# STM32L496 register map
File version: 1.0
CPU: CM4 r0p1, little endian, MPU, FPU, 4 interrupt priority bits
Registers are 32-bit, read-write, reset 0x0 unless marked. A register's access mark holds for its fields unless they carry their own. Offsets are from the block's base; [hi:lo] are bit positions; {n}, {i} and the like mark numbered series; 'fields as' and 'values as' point back to an identical list.

## HASH — Hash processor
Base 0x50060400
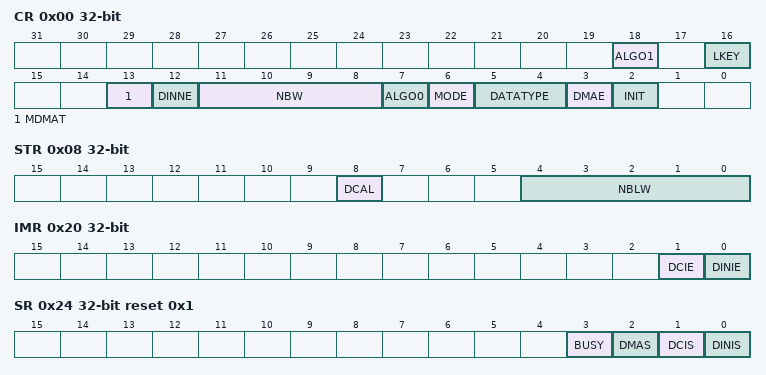
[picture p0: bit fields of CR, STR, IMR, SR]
0x00 CR access per field — control register
  [18] ALGO1 rw — ALGO
  [16] LKEY rw — Long key selection
  [13] MDMAT rw — Multiple DMA Transfers
  [12] DINNE ro — DIN not empty
  [11:8] NBW ro — Number of words already pushed
  [7] ALGO0 rw — Algorithm selection
  [6] MODE rw — Mode selection
  [5:4] DATATYPE rw — Data type selection
  [3] DMAE rw — DMA enable
  [2] INIT wo — Initialize message digest calculation
0x04 DIN — data input register
  [31:0] DATAIN — Data input
0x08 STR access per field — start register
  [8] DCAL wo — Digest calculation
  [4:0] NBLW rw — Number of valid bits in the last word of the message
0x0C HR0 ro — digest registers
  [31:0] H0
0x20 IMR — interrupt enable register
  [1] DCIE — Digest calculation completion interrupt enable
  [0] DINIE — Data input interrupt enable
0x24 SR access per field reset 0x1 — status register
  [3] BUSY ro — Busy bit
  [2] DMAS ro — DMA Status
  [1] DCIS rw — Digest calculation completion interrupt status
  [0] DINIS rw — Data input interrupt status
{0xF8+4i} CSR{i} (i=0..53) — context swap registers
0x310 HASH_HR0 ro — HASH digest register
  [31:0] H0
{0x310+4i} HASH_HR{i} ro (i=1..7) — read-only
  [31:0] H{i}

## DMA2D — DMA2D controller
Base 0x4002B000
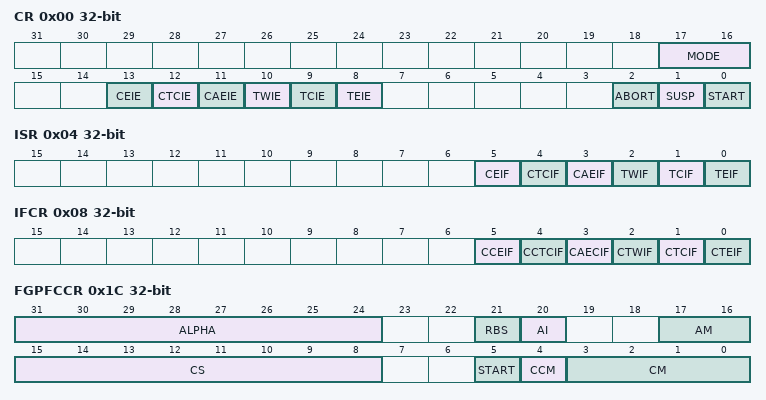
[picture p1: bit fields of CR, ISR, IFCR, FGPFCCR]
0x00 CR — control register
  [17:16] MODE — DMA2D mode
  [13] CEIE — Configuration Error Interrupt Enable
  [12] CTCIE — CLUT transfer complete interrupt enable
  [11] CAEIE — CLUT access error interrupt enable
  [10] TWIE — Transfer watermark interrupt enable
  [9] TCIE — Transfer complete interrupt enable
  [8] TEIE — Transfer error interrupt enable
  [2] ABORT
  [1] SUSP — Suspend
  [0] START
0x04 ISR ro — Interrupt Status Register
  [5] CEIF — Configuration error interrupt flag
  [4] CTCIF — CLUT transfer complete interrupt flag
  [3] CAEIF — CLUT access error interrupt flag
  [2] TWIF — Transfer watermark interrupt flag
  [1] TCIF — Transfer complete interrupt flag
  [0] TEIF — Transfer error interrupt flag
0x08 IFCR — interrupt flag clear register
  [5] CCEIF — Clear configuration error interrupt flag
  [4] CCTCIF — Clear CLUT transfer complete interrupt flag
  [3] CAECIF — Clear CLUT access error interrupt flag
  [2] CTWIF — Clear transfer watermark interrupt flag
  [1] CTCIF — Clear transfer complete interrupt flag
  [0] CTEIF — Clear Transfer error interrupt flag
0x0C FGMAR — foreground memory address register
  [31:0] MA — Memory address
0x10 FGOR — foreground offset register
  [13:0] LO — Line offset
0x14 BGMAR — background memory address register
  [31:0] MA — Memory address
0x18 BGOR — background offset register
  [13:0] LO — Line offset
0x1C FGPFCCR — foreground PFC control register
  [31:24] ALPHA — Alpha value
  [21] RBS — Red Blue Swap
  [20] AI — Alpha Inverted
  [17:16] AM — Alpha mode
  [15:8] CS — CLUT size
  [5] START
  [4] CCM — CLUT color mode
  [3:0] CM — Color mode
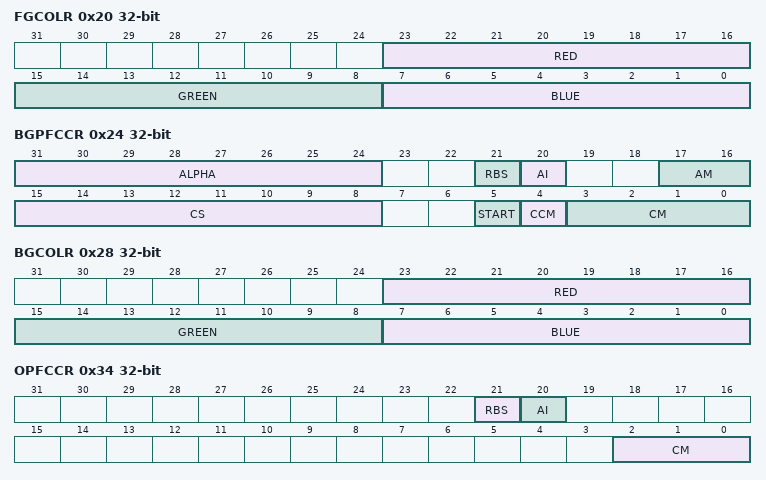
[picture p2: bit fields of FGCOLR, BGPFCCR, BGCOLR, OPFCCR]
0x20 FGCOLR — foreground color register
  [23:16] RED — Red Value
  [15:8] GREEN — Green Value
  [7:0] BLUE — Blue Value
0x24 BGPFCCR — background PFC control register
  [31:24] ALPHA — Alpha value
  [21] RBS — Red Blue Swap
  [20] AI — Alpha Inverted
  [17:16] AM — Alpha mode
  [15:8] CS — CLUT size
  [5] START
  [4] CCM — CLUT Color mode
  [3:0] CM — Color mode
0x28 BGCOLR — background color register
  fields as FGCOLR
0x2C FGCMAR — foreground CLUT memory address register
  [31:0] MA — Memory Address
0x30 BGCMAR — background CLUT memory address register
  [31:0] MA — Memory address
0x34 OPFCCR — output PFC control register
  [21] RBS — Red Blue Swap
  [20] AI — Alpha Inverted
  [2:0] CM — Color mode
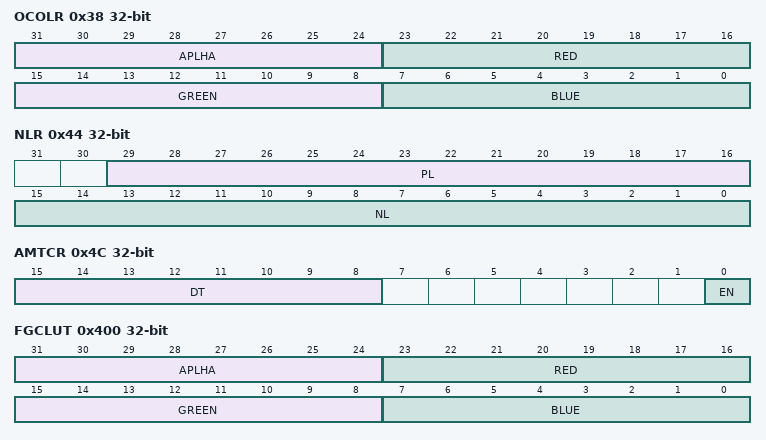
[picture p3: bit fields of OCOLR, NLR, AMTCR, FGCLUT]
0x38 OCOLR — output color register
  [31:24] APLHA — Alpha Channel Value
  [23:16] RED — Red Value
  [15:8] GREEN — Green Value
  [7:0] BLUE — Blue Value
0x3C OMAR — output memory address register
  [31:0] MA — Memory Address
0x40 OOR — output offset register
  [13:0] LO — Line Offset
0x44 NLR — number of line register
  [29:16] PL — Pixel per lines
  [15:0] NL — Number of lines
0x48 LWR — line watermark register
  [15:0] LW — Line watermark
0x4C AMTCR — AHB master timer configuration register
  [15:8] DT — Dead Time
  [0] EN — Enable
0x400 FGCLUT
  [31:24] APLHA, [23:16] RED, [15:8] GREEN, [7:0] BLUE
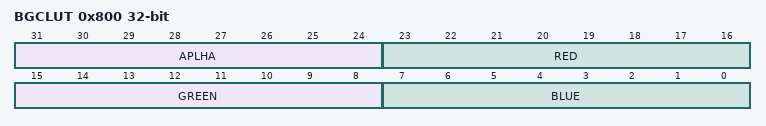
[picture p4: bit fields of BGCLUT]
0x800 BGCLUT
  [31:24] APLHA, [23:16] RED, [15:8] GREEN, [7:0] BLUE

## FPU — Floting point unit
Base 0xE000EF34
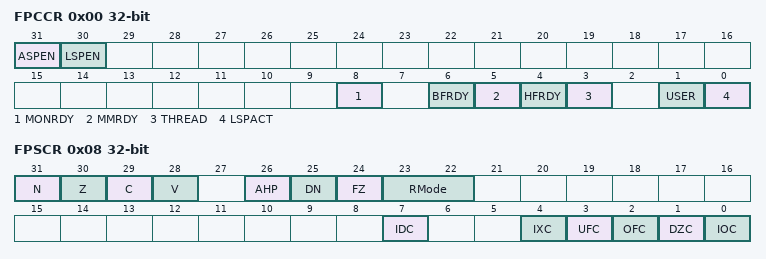
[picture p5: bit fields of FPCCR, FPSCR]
0x00 FPCCR — Floating-point context control register
  [31] ASPEN, [30] LSPEN, [8] MONRDY, [6] BFRDY, [5] MMRDY, [4] HFRDY, [3] THREAD, [1] USER, [0] LSPACT
0x04 FPCAR — Floating-point context address register
  [31:3] ADDRESS — Location of unpopulated floating-point
0x08 FPSCR — Floating-point status control register
  [31] N — Negative condition code flag
  [30] Z — Zero condition code flag
  [29] C — Carry condition code flag
  [28] V — Overflow condition code flag
  [26] AHP — Alternative half-precision control bit
  [25] DN — Default NaN mode control bit
  [24] FZ — Flush-to-zero mode control bit:
  [23:22] RMode — Rounding Mode control field
  [7] IDC — Input denormal cumulative exception bit.
  [4] IXC — Inexact cumulative exception bit
  [3] UFC — Underflow cumulative exception bit
  [2] OFC — Overflow cumulative exception bit
  [1] DZC — Division by zero cumulative exception bit.
  [0] IOC — Invalid operation cumulative exception bit

## MPU — Memory protection unit
Base 0xE000ED90
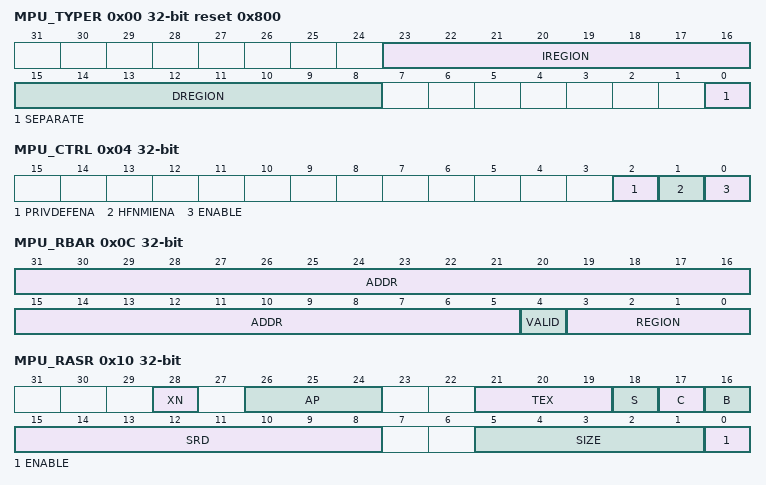
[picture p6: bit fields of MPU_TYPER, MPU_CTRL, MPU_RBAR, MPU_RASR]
0x00 MPU_TYPER ro reset 0x800 — MPU type register
  [23:16] IREGION — Number of MPU instruction regions
  [15:8] DREGION — Number of MPU data regions
  [0] SEPARATE — Separate flag
0x04 MPU_CTRL ro — MPU control register
  [2] PRIVDEFENA — Enable priviliged software access to default memory map
  [1] HFNMIENA — Enables the operation of MPU during hard fault
  [0] ENABLE — Enables the MPU
0x08 MPU_RNR — MPU region number register
  [7:0] REGION — MPU region
0x0C MPU_RBAR — MPU region base address register
  [31:5] ADDR — Region base address field
  [4] VALID — MPU region number valid
  [3:0] REGION — MPU region field
0x10 MPU_RASR — MPU region attribute and size register
  [28] XN — Instruction access disable bit
  [26:24] AP — Access permission
  [21:19] TEX — memory attribute
  [18] S — Shareable memory attribute
  [17] C — memory attribute
  [16] B — memory attribute
  [15:8] SRD — Subregion disable bits
  [5:1] SIZE — Size of the MPU protection region
  [0] ENABLE — Region enable bit.

## STK — SysTick timer
Base 0xE000E010
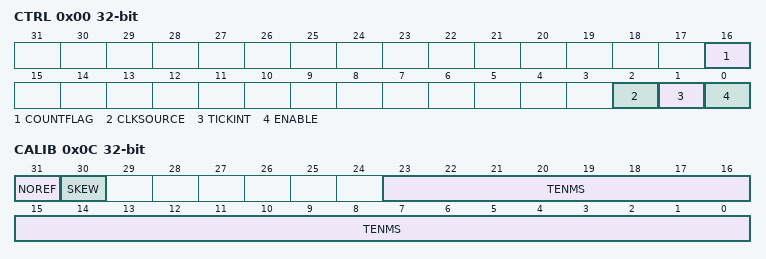
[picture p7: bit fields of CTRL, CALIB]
0x00 CTRL — SysTick control and status register
  [16] COUNTFLAG
  [2] CLKSOURCE — Clock source selection
  [1] TICKINT — SysTick exception request enable
  [0] ENABLE — Counter enable
0x04 LOAD — SysTick reload value register
  [23:0] RELOAD — RELOAD value
0x08 VAL — SysTick current value register
  [23:0] CURRENT — Current counter value
0x0C CALIB — SysTick calibration value register
  [31] NOREF — NOREF flag. Reads as zero
  [30] SKEW — SKEW flag: Indicates whether the TENMS value is exact
  [23:0] TENMS — Calibration value

## NVIC_STIR — Nested vectored interrupt controller
Base 0xE000EF00
0x00 STIR — Software trigger interrupt register
  [8:0] INTID — Software generated interrupt ID

## FPU_CPACR — Floating point unit CPACR
Base 0xE000ED88
0x00 CPACR — Coprocessor access control register
  [23:20] CP

## SCB_ACTRL — System control block ACTLR
Base 0xE000E008
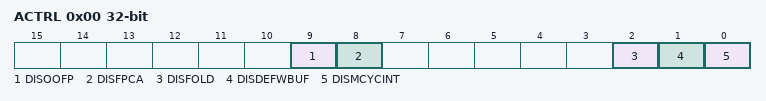
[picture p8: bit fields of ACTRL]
0x00 ACTRL — Auxiliary control register
  [9] DISOOFP, [8] DISFPCA, [2] DISFOLD, [1] DISDEFWBUF, [0] DISMCYCINT
